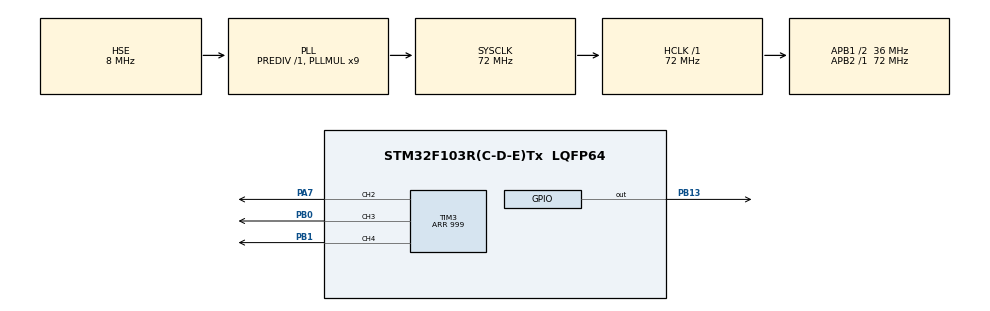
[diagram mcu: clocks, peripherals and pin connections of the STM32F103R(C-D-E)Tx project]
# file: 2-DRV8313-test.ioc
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Mcu.Family=STM32F1
Mcu.Name=STM32F103R(C-D-E)Tx
Mcu.Package=LQFP64
NVIC.PriorityGroup=NVIC_PRIORITYGROUP_4
PA13.Mode=Serial_Wire
PA13.Signal=SYS_JTMS-SWDIO
PA14.Mode=Serial_Wire
PA14.Signal=SYS_JTCK-SWCLK
PA7.Signal=S_TIM3_CH2
PB0.Signal=S_TIM3_CH3
PB1.Signal=S_TIM3_CH4
PB13.Signal=GPIO_Output
PD0-OSC_IN.Mode=HSE-External-Oscillator
PD0-OSC_IN.Signal=RCC_OSC_IN
PD1-OSC_OUT.Mode=HSE-External-Oscillator
PD1-OSC_OUT.Signal=RCC_OSC_OUT
ProjectManager.HeapSize=0x200
ProjectManager.StackSize=0x400
ProjectManager.TargetToolchain=STM32CubeIDE
RCC.AHBFreq_Value=72000000
RCC.APB1CLKDivider=RCC_HCLK_DIV2
RCC.APB1Freq_Value=36000000
RCC.APB1TimFreq_Value=72000000
RCC.APB2Freq_Value=72000000
RCC.APB2TimFreq_Value=72000000
RCC.HCLKFreq_Value=72000000
RCC.PLLMUL=RCC_PLL_MUL9
RCC.PLLSourceVirtual=RCC_PLLSOURCE_HSE
RCC.SYSCLKFreq_VALUE=72000000
RCC.SYSCLKSource=RCC_SYSCLKSOURCE_PLLCLK
RCC.USBFreq_Value=72000000
SH.S_TIM3_CH2.0=TIM3_CH2,PWM Generation2 CH2
SH.S_TIM3_CH3.0=TIM3_CH3,PWM Generation3 CH3
SH.S_TIM3_CH4.0=TIM3_CH4,PWM Generation4 CH4
TIM3.AutoReloadPreload=TIM_AUTORELOAD_PRELOAD_ENABLE
TIM3.Channel-PWM\ Generation2\ CH2=TIM_CHANNEL_2
TIM3.Channel-PWM\ Generation3\ CH3=TIM_CHANNEL_3
TIM3.Channel-PWM\ Generation4\ CH4=TIM_CHANNEL_4
TIM3.Period=999
board=custom

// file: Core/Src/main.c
/* USER CODE BEGIN Header */
/**
  ******************************************************************************
  * @file           : main.c
  * @brief          : Main program body
  ******************************************************************************
  * @attention
  *
  * Copyright (c) 2026 STMicroelectronics.
  * All rights reserved.
  *
  * This software is licensed under terms that can be found in the LICENSE file
  * in the root directory of this software component.
  * If no LICENSE file comes with this software, it is provided AS-IS.
  *
  ******************************************************************************
  */
/* USER CODE END Header */
#include "main.h"

/* USER CODE BEGIN Includes */
#include "motor.h"
/* USER CODE END Includes */

TIM_HandleTypeDef htim3;

void SystemClock_Config(void);
static void MX_GPIO_Init(void);
static void MX_TIM3_Init(void);

int main(void)
{

  /* MCU Configuration--------------------------------------------------------*/

  /* Reset of all peripherals, Initializes the Flash interface and the Systick. */
  HAL_Init();

  /* Configure the system clock */
  SystemClock_Config();

  /* Initialize all configured peripherals */
  MX_GPIO_Init();
  MX_TIM3_Init();
  /* USER CODE BEGIN 2 */
  HAL_GPIO_WritePin(GPIOB, GPIO_PIN_13, GPIO_PIN_SET);
  /* If nSLEEP is driven by a GPIO, enable DRV8313 first */
      // HAL_GPIO_WritePin(NSLEEP_GPIO_Port, NSLEEP_Pin, GPIO_PIN_SET);

      Motor_Init(&htim3);

      /* CHOOSE ONE TEST: */

      /* Option A — Sweep then hold at 0° (recommended first test) */
      Motor_SweepTest();

      /* Option B — Hold at a specific angle immediately */
      // while(1) { Motor_HoldPosition(90.0f, HOLD_STRENGTH); HAL_Delay(1); }

      /* Option C — Coast (motor off) */
      // Motor_Coast();
  /* USER CODE END 2 */

  /* Infinite loop */
  while (1)
  {

  }
}

void SystemClock_Config(void)
{
  RCC_OscInitTypeDef RCC_OscInitStruct = {0};
  RCC_ClkInitTypeDef RCC_ClkInitStruct = {0};

  /** Initializes the RCC Oscillators according to the specified parameters
  * in the RCC_OscInitTypeDef structure.
  */
  RCC_OscInitStruct.OscillatorType = RCC_OSCILLATORTYPE_HSE;
  RCC_OscInitStruct.HSEState = RCC_HSE_ON;
  RCC_OscInitStruct.HSEPredivValue = RCC_HSE_PREDIV_DIV1;
  RCC_OscInitStruct.HSIState = RCC_HSI_ON;
  RCC_OscInitStruct.PLL.PLLState = RCC_PLL_ON;
  RCC_OscInitStruct.PLL.PLLSource = RCC_PLLSOURCE_HSE;
  RCC_OscInitStruct.PLL.PLLMUL = RCC_PLL_MUL9;
  if (HAL_RCC_OscConfig(&RCC_OscInitStruct) != HAL_OK)
  {
    Error_Handler();
  }

  /** Initializes the CPU, AHB and APB buses clocks
  */
  RCC_ClkInitStruct.ClockType = RCC_CLOCKTYPE_HCLK|RCC_CLOCKTYPE_SYSCLK
                              |RCC_CLOCKTYPE_PCLK1|RCC_CLOCKTYPE_PCLK2;
  RCC_ClkInitStruct.SYSCLKSource = RCC_SYSCLKSOURCE_PLLCLK;
  RCC_ClkInitStruct.AHBCLKDivider = RCC_SYSCLK_DIV1;
  RCC_ClkInitStruct.APB1CLKDivider = RCC_HCLK_DIV2;
  RCC_ClkInitStruct.APB2CLKDivider = RCC_HCLK_DIV1;

  if (HAL_RCC_ClockConfig(&RCC_ClkInitStruct, FLASH_LATENCY_2) != HAL_OK)
  {
    Error_Handler();
  }
}

static void MX_TIM3_Init(void)
{

  TIM_MasterConfigTypeDef sMasterConfig = {0};
  TIM_OC_InitTypeDef sConfigOC = {0};

  htim3.Instance = TIM3;
  htim3.Init.Prescaler = 0;
  htim3.Init.CounterMode = TIM_COUNTERMODE_UP;
  htim3.Init.Period = 999;
  htim3.Init.ClockDivision = TIM_CLOCKDIVISION_DIV1;
  htim3.Init.AutoReloadPreload = TIM_AUTORELOAD_PRELOAD_ENABLE;
  if (HAL_TIM_PWM_Init(&htim3) != HAL_OK)
  {
    Error_Handler();
  }
  sMasterConfig.MasterOutputTrigger = TIM_TRGO_RESET;
  sMasterConfig.MasterSlaveMode = TIM_MASTERSLAVEMODE_DISABLE;
  if (HAL_TIMEx_MasterConfigSynchronization(&htim3, &sMasterConfig) != HAL_OK)
  {
    Error_Handler();
  }
  sConfigOC.OCMode = TIM_OCMODE_PWM1;
  sConfigOC.Pulse = 0;
  sConfigOC.OCPolarity = TIM_OCPOLARITY_HIGH;
  sConfigOC.OCFastMode = TIM_OCFAST_DISABLE;
  if (HAL_TIM_PWM_ConfigChannel(&htim3, &sConfigOC, TIM_CHANNEL_2) != HAL_OK)
  {
    Error_Handler();
  }
  if (HAL_TIM_PWM_ConfigChannel(&htim3, &sConfigOC, TIM_CHANNEL_3) != HAL_OK)
  {
    Error_Handler();
  }
  if (HAL_TIM_PWM_ConfigChannel(&htim3, &sConfigOC, TIM_CHANNEL_4) != HAL_OK)
  {
    Error_Handler();
  }
  HAL_TIM_MspPostInit(&htim3);

}

static void MX_GPIO_Init(void)
{
  GPIO_InitTypeDef GPIO_InitStruct = {0};

  /* GPIO Ports Clock Enable */
  __HAL_RCC_GPIOD_CLK_ENABLE();
  __HAL_RCC_GPIOA_CLK_ENABLE();
  __HAL_RCC_GPIOB_CLK_ENABLE();

  /*Configure GPIO pin Output Level */
  HAL_GPIO_WritePin(GPIOB, GPIO_PIN_13, GPIO_PIN_RESET);

  /*Configure GPIO pin : PB13 */
  GPIO_InitStruct.Pin = GPIO_PIN_13;
  GPIO_InitStruct.Mode = GPIO_MODE_OUTPUT_PP;
  GPIO_InitStruct.Pull = GPIO_NOPULL;
  GPIO_InitStruct.Speed = GPIO_SPEED_FREQ_LOW;
  HAL_GPIO_Init(GPIOB, &GPIO_InitStruct);

}

void Error_Handler(void)
{
  __disable_irq();
  while (1)
  {
  }
}
